VERSION ""

NS_ :

BS_:

BU_: XXX

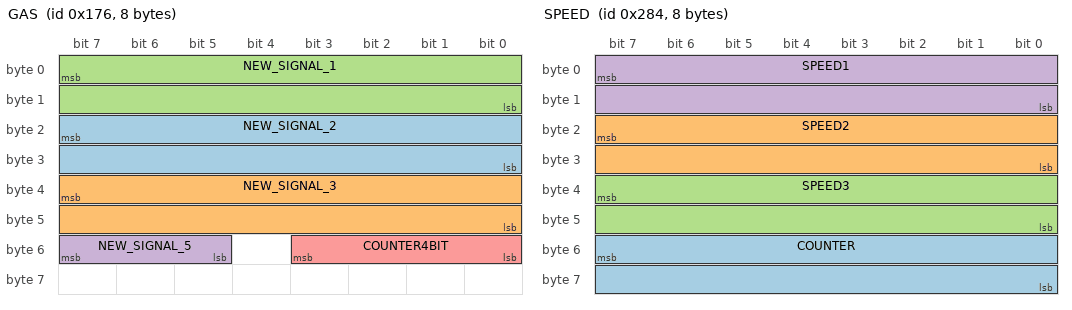
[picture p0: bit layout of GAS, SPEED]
BO_ 374 GAS: 8 XXX
 SG_ NEW_SIGNAL_2 : 23|16@0+ (1,0) [0|65535] "" XXX
 SG_ NEW_SIGNAL_3 : 39|16@0+ (1,0) [0|65535] "" XXX
 SG_ NEW_SIGNAL_1 : 7|16@0+ (1,0) [0|65535] "" XXX
 SG_ NEW_SIGNAL_5 : 55|3@0+ (1,0) [0|7] "" XXX
 SG_ COUNTER4BIT : 48|4@1+ (1,0) [0|15] "" XXX

BO_ 644 SPEED: 8 XXX
 SG_ COUNTER : 55|16@0+ (1,0) [0|65535] "" XXX
 SG_ SPEED2 : 23|16@0+ (1,0) [0|65535] "" XXX
 SG_ SPEED3 : 39|16@0+ (1,0) [0|255] "" XXX
 SG_ SPEED1 : 7|16@0+ (1,0) [0|255] "" XXX

BO_ 658 NEW_MSG_2: 8 XXX
 SG_ NEW_SIGNAL_1 : 15|8@0+ (1,0) [0|255] "" XXX
 SG_ NEW_SIGNAL_2 : 7|8@0+ (1,0) [0|255] "" XXX
 SG_ NEW_SIGNAL_3 : 23|0@0+ (1,0) [0|255] "" XXX

BO_ 768 STEERING: 8 XXX
 SG_ STEER_TORQUE : 7|8@0+ (1,0) [0|255] "" XXX

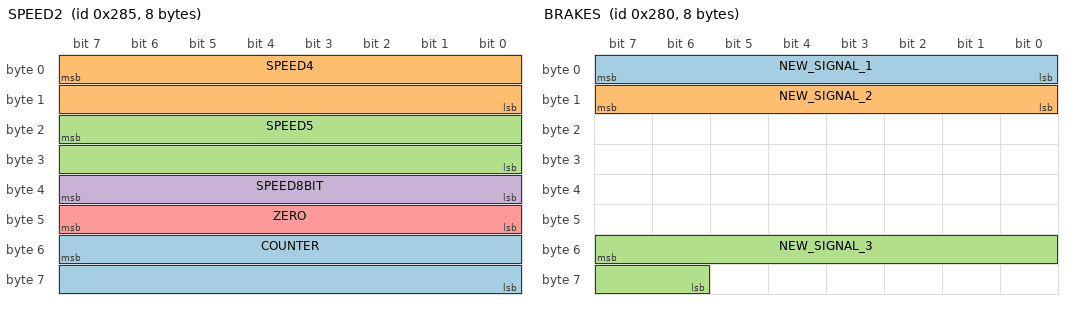
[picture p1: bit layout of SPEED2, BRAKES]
BO_ 645 SPEED2: 8 XXX
 SG_ COUNTER : 55|16@0+ (1,0) [0|255] "" XXX
 SG_ SPEED4 : 7|16@0+ (1,0) [0|65535] "" XXX
 SG_ SPEED5 : 23|16@0+ (1,0) [0|65535] "" XXX
 SG_ SPEED8BIT : 39|8@0+ (1,0) [0|65535] "" XXX
 SG_ ZERO : 47|8@0+ (1,0) [0|255] "" XXX

BO_ 1666 NEW_MSG_1: 8 XXX
 SG_ NEW_SIGNAL_1 : 7|64@0+ (1,0) [0|18446744073709552000] "" XXX

BO_ 1762 NEW_MSG_3: 8 XXX
 SG_ NEW_SIGNAL_1 : 45|4@0+ (1,0) [0|18446744073709552000] "" XXX
 SG_ NEW_SIGNAL_2 : 47|8@0+ (1,0) [0|255] "" XXX
 SG_ NEW_SIGNAL_3 : 17|2@1+ (1,0) [0|3] "" XXX
 SG_ SEVEN : 22|3@0+ (1,0) [0|127] "" XXX

BO_ 640 BRAKES: 8 XXX
 SG_ NEW_SIGNAL_1 : 7|8@0+ (1,0) [0|255] "" XXX
 SG_ NEW_SIGNAL_2 : 15|8@0+ (1,0) [0|255] "" XXX
 SG_ NEW_SIGNAL_3 : 55|10@0+ (1,0) [0|255] "" XXX

BO_ 1004 SUSPENSION: 8 XXX
 SG_ NEW_SIGNAL_1 : 7|16@0+ (1,0) [0|65535] "" XXX

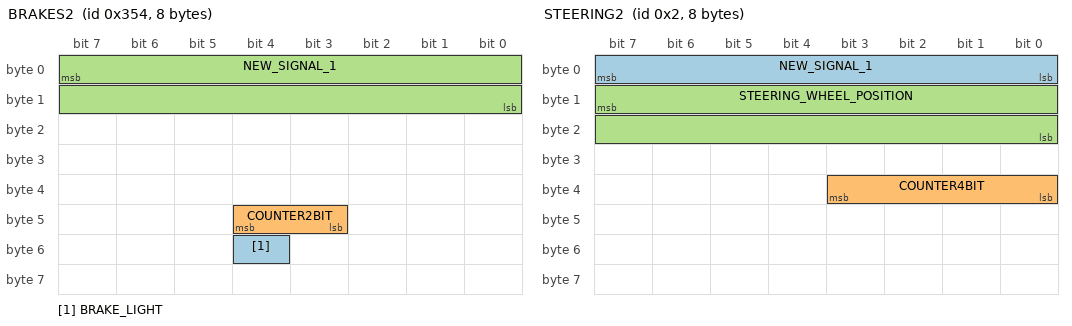
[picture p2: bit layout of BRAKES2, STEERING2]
BO_ 852 BRAKES2: 8 XXX
 SG_ BRAKE_LIGHT : 52|1@0+ (1,0) [0|1] "" XXX
 SG_ COUNTER2BIT : 44|2@0+ (1,0) [0|3] "" XXX
 SG_ NEW_SIGNAL_1 : 7|16@0+ (1,0) [0|65535] "" XXX

BO_ 2 STEERING2: 8 XXX
 SG_ NEW_SIGNAL_1 : 7|8@0+ (1,0) [0|255] "" XXX
 SG_ COUNTER4BIT : 35|4@0+ (1,0) [0|255] "" XXX
 SG_ STEERING_WHEEL_POSITION : 15|16@0- (1,0) [0|255] "" XXX

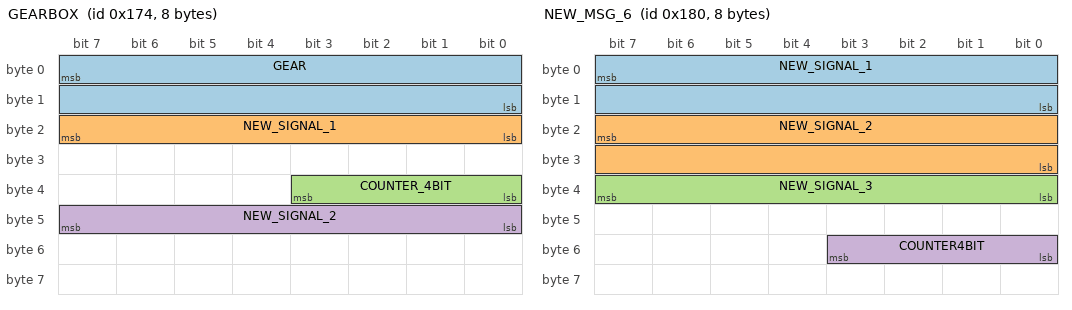
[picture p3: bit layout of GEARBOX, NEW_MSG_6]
BO_ 372 GEARBOX: 8 XXX
 SG_ GEAR : 7|16@0+ (1,0) [0|255] "" XXX
 SG_ NEW_SIGNAL_1 : 23|8@0+ (1,0) [0|255] "" XXX
 SG_ COUNTER_4BIT : 35|4@0+ (1,0) [0|255] "" XXX
 SG_ NEW_SIGNAL_2 : 47|8@0+ (1,0) [0|255] "" XXX

BO_ 1361 NEW_MSG_4: 8 XXX
 SG_ COUNTER16BIT : 7|16@0+ (1,0) [0|65535] "" XXX

BO_ 1408 NEW_MSG_5: 8 XXX
 SG_ NEW_SIGNAL_1 : 7|16@0+ (1,0) [0|65535] "" XXX
 SG_ NEW_SIGNAL_2 : 23|8@0+ (1,0) [0|255] "" XXX

BO_ 384 NEW_MSG_6: 8 XXX
 SG_ NEW_SIGNAL_1 : 7|16@0+ (1,0) [0|65535] "" XXX
 SG_ NEW_SIGNAL_2 : 23|16@0+ (1,0) [0|65535] "" XXX
 SG_ NEW_SIGNAL_3 : 39|8@0+ (1,0) [0|255] "" XXX
 SG_ COUNTER4BIT : 51|4@0+ (1,0) [0|255] "" XXX

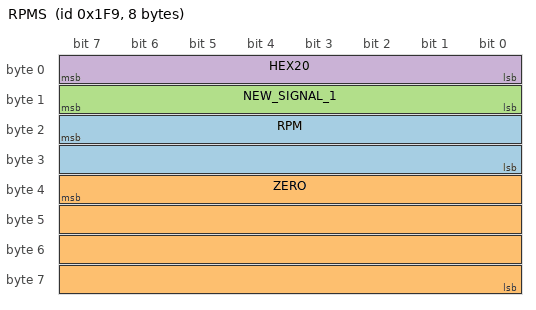
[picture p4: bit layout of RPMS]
BO_ 505 RPMS: 8 XXX
 SG_ RPM : 23|16@0+ (1,0) [0|65535] "" XXX
 SG_ ZERO : 39|32@0+ (1,0) [0|4294967295] "" XXX
 SG_ NEW_SIGNAL_1 : 15|8@0+ (1,0) [0|255] "" XXX
 SG_ HEX20 : 7|8@0+ (1,0) [0|255] "" XXX

BO_ 853 NEW_MSG_7: 8 XXX
 SG_ NEW_SIGNAL_1 : 7|16@0+ (1,0) [0|65535] "" XXX
